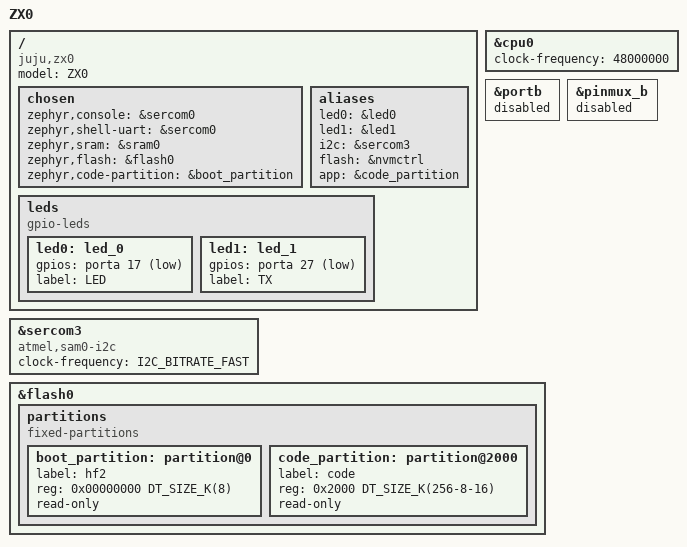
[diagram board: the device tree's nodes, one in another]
/*
 * Copyright (c) 2021 Google LLC.
 *
 * SPDX-License-Identifier: Apache-2.0
 */

/dts-v1/;
#include <atmel/samd21.dtsi>

/ {
	model = "ZX0";
	compatible = "juju,zx0", "atmel,samd21e18a", "atmel,samd21";

	chosen {
		zephyr,console = &sercom0;
		zephyr,shell-uart = &sercom0;
		zephyr,sram = &sram0;
		zephyr,flash = &flash0;
		zephyr,code-partition = &boot_partition;
	};

	aliases {
		led0 = &led0;
		led1 = &led1;
		i2c = &sercom3;
		flash = &nvmctrl;
		app = &code_partition;
	};

	leds {
		compatible = "gpio-leds";
		led0: led_0 {
			gpios = <&porta 17 GPIO_ACTIVE_LOW>;
			label = "LED";
		};
		led1: led_1 {
			gpios = <&porta 27 GPIO_ACTIVE_LOW>;
			label = "TX";
		};
	};

};

&cpu0 {
	clock-frequency = <48000000>;
};

&portb {
	status = "disabled";
};

&pinmux_b {
	status = "disabled";
};

&sercom3 {
	status = "okay";
	compatible = "atmel,sam0-i2c";
	clock-frequency = <I2C_BITRATE_FAST>;
	#address-cells = <1>;
	#size-cells = <0>;
};

&flash0 {
	partitions {
		compatible = "fixed-partitions";
		#address-cells = <1>;
		#size-cells = <1>;

		boot_partition: partition@0 {
			label = "hf2";
			reg = <0x00000000 DT_SIZE_K(8)>;
			read-only;
		};

		code_partition: partition@2000 {
			label = "code";
			reg = <0x2000 DT_SIZE_K(256-8-16)>;
			read-only;
		};
	};
};
